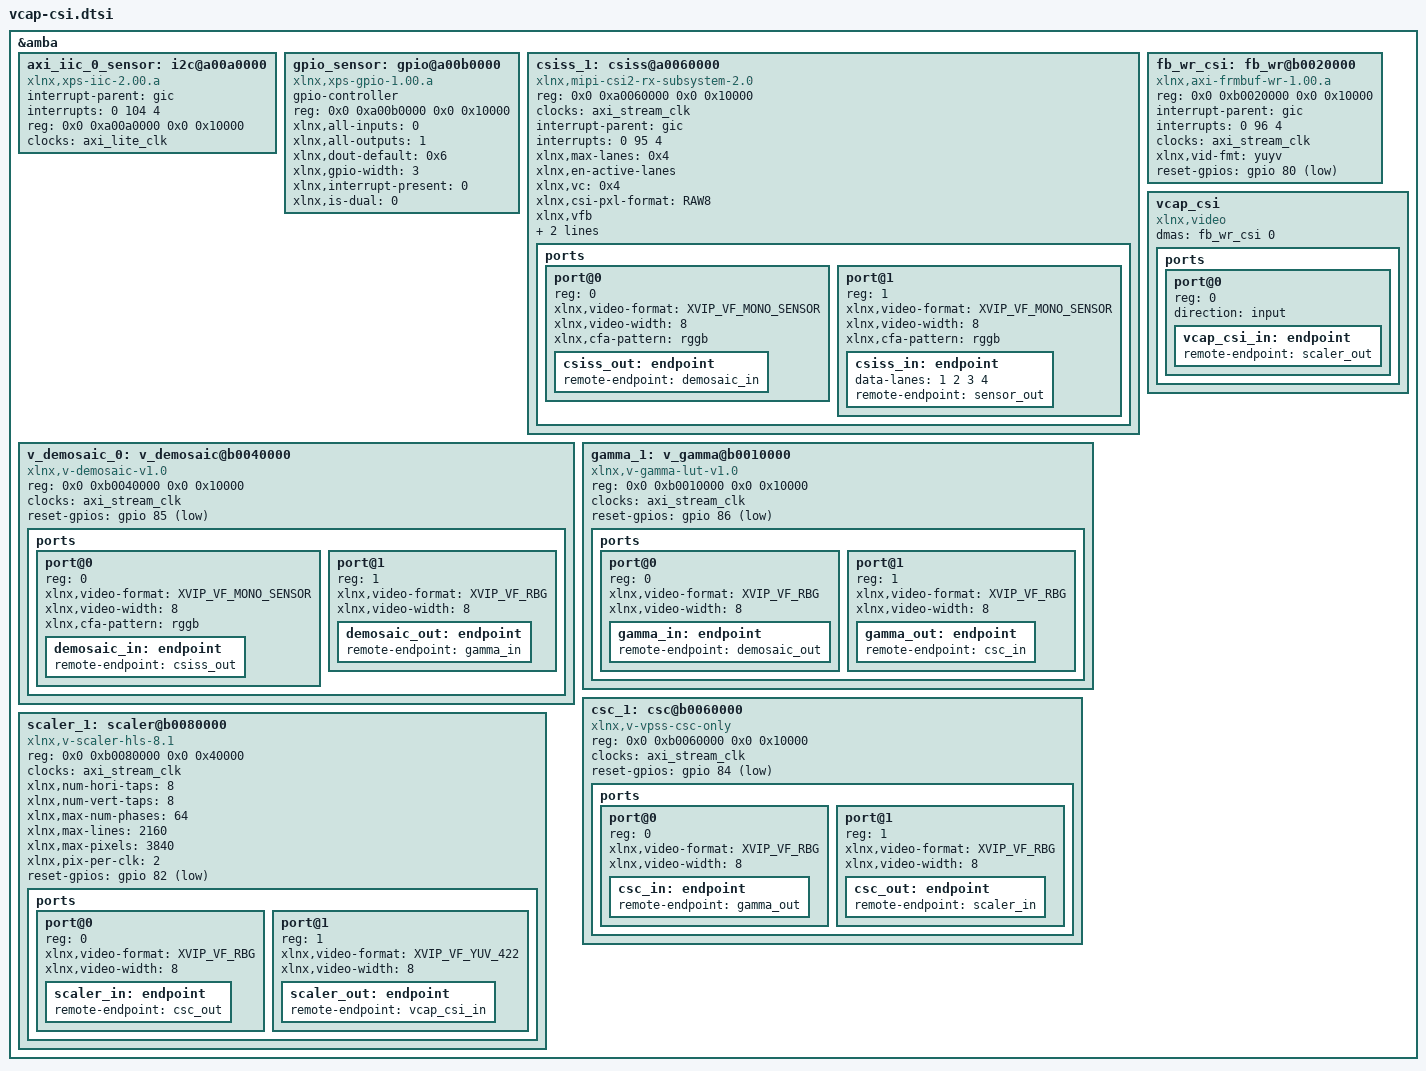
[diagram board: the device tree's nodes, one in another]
#include <dt-bindings/media/xilinx-vip.h>

&amba {
	axi_iic_0_sensor: i2c@a00a0000 {
		#address-cells = <1>;
		#size-cells = <0>;
		compatible = "xlnx,xps-iic-2.00.a";
		interrupt-parent = <&gic>;
		interrupts = <0 104 4>;
		reg = <0x0 0xa00a0000 0x0 0x10000>;
		clocks = <&axi_lite_clk>;
	};

	gpio_sensor: gpio@a00b0000 {
		#gpio-cells = <2>;
		compatible = "xlnx,xps-gpio-1.00.a";
		gpio-controller;
		reg = <0x0 0xa00b0000 0x0 0x10000>;

		xlnx,all-inputs = <0>;
		xlnx,all-outputs = <1>;
		xlnx,dout-default = <0x6>;
		xlnx,gpio-width = <3>;
		xlnx,interrupt-present = <0>;
		xlnx,is-dual = <0>;
	} ;

	csiss_1: csiss@a0060000 {
		compatible = "xlnx,mipi-csi2-rx-subsystem-2.0";
		reg = <0x0 0xa0060000 0x0 0x10000>;
		clocks = <&axi_stream_clk>;
		interrupt-parent = <&gic>;
		interrupts = <0 95 4>;

		xlnx,max-lanes = <0x4>;
		xlnx,en-active-lanes;
		xlnx,vc = <0x4>;
		xlnx,csi-pxl-format = "RAW8";
		xlnx,vfb;
		xlnx,ppc = <0x4>;
		xlnx,axis-tdata-width = <0x20>;

		ports {
			#address-cells = <1>;
			#size-cells = <0>;

			port@0 {
				reg = <0>;

				xlnx,video-format = <XVIP_VF_MONO_SENSOR>;
				xlnx,video-width = <8>;
				xlnx,cfa-pattern = "rggb";

				csiss_out: endpoint {
					remote-endpoint = <&demosaic_in>;
				};
			};
			port@1 {
				reg = <1>;

				xlnx,video-format = <XVIP_VF_MONO_SENSOR>;
				xlnx,video-width = <8>;
				xlnx,cfa-pattern = "rggb";

				csiss_in: endpoint {
					data-lanes = <1 2 3 4>;
					remote-endpoint = <&sensor_out>;
				};
			};
		};
	};

	v_demosaic_0: v_demosaic@b0040000 {
		compatible = "xlnx,v-demosaic-v1.0";
		reg = <0x0 0xb0040000 0x0 0x10000>;
		clocks = <&axi_stream_clk>;

		reset-gpios = <&gpio 85 1>;

		ports {
			#address-cells = <1>;
			#size-cells = <0>;

			port@0 {
				reg = <0>;

				xlnx,video-format = <XVIP_VF_MONO_SENSOR>;
				xlnx,video-width = <8>;
				xlnx,cfa-pattern = "rggb";

				demosaic_in: endpoint {
					remote-endpoint = <&csiss_out>;
				};
			};

			port@1 {
				reg = <1>;

				xlnx,video-format = <XVIP_VF_RBG>;
				xlnx,video-width = <8>;

				demosaic_out: endpoint {
					remote-endpoint = <&gamma_in>;
				};
			};
		};
	};

	gamma_1: v_gamma@b0010000 {
		compatible = "xlnx,v-gamma-lut-v1.0";
		reg = <0x0 0xb0010000 0x0 0x10000>;
		clocks = <&axi_stream_clk>;

		reset-gpios = <&gpio 86 1>;

		ports {
			#address-cells = <1>;
			#size-cells = <0>;

			port@0 {
				reg = <0>;

				xlnx,video-format = <XVIP_VF_RBG>;
				xlnx,video-width = <8>;

				gamma_in: endpoint {
					remote-endpoint = <&demosaic_out>;
				};
			};

			port@1 {
				reg = <1>;

				xlnx,video-format = <XVIP_VF_RBG>;
				xlnx,video-width = <8>;

				gamma_out: endpoint {
					remote-endpoint = <&csc_in>;
				};
			};
		};
	};

	csc_1: csc@b0060000 {
		compatible = "xlnx,v-vpss-csc-only";
		reg = <0x0 0xb0060000 0x0 0x10000>;
		clocks = <&axi_stream_clk>;

		reset-gpios = <&gpio 84 1>;

		ports {
			#address-cells = <1>;
			#size-cells = <0>;

			port@0 {
				reg = <0>;

				xlnx,video-format = <XVIP_VF_RBG>;
				xlnx,video-width = <8>;

				csc_in: endpoint {
					remote-endpoint = <&gamma_out>;
				};
			};
			port@1 {
				reg = <1>;

				xlnx,video-format = <XVIP_VF_RBG>;
				xlnx,video-width = <8>;

				csc_out: endpoint {
					remote-endpoint = <&scaler_in>;
				};
			};
		};
	};

	scaler_1: scaler@b0080000 {
		compatible = "xlnx,v-scaler-hls-8.1";
		reg = <0x0 0xb0080000 0x0 0x40000>;
		clocks = <&axi_stream_clk>;

		xlnx,num-hori-taps = <8>;
		xlnx,num-vert-taps = <8>;
		xlnx,max-num-phases = <64>;
		xlnx,max-lines = <2160>;
		xlnx,max-pixels = <3840>;
		xlnx,pix-per-clk = <2>;

		reset-gpios = <&gpio 82 1>;

		ports {
			#address-cells = <1>;
			#size-cells = <0>;

			port@0 {
				reg = <0>;

				xlnx,video-format = <XVIP_VF_RBG>;
				xlnx,video-width = <8>;

				scaler_in: endpoint {
					remote-endpoint = <&csc_out>;
				};
			};
			port@1 {
				reg = <1>;

				xlnx,video-format = <XVIP_VF_YUV_422>;
				xlnx,video-width = <8>;

				scaler_out: endpoint {
					remote-endpoint = <&vcap_csi_in>;
				};
			};
		};
	};

	fb_wr_csi: fb_wr@b0020000 {
		compatible = "xlnx,axi-frmbuf-wr-1.00.a";
		reg = <0x0 0xb0020000 0x0 0x10000>;
		#dma-cells = <1>;
		interrupt-parent = <&gic>;
		interrupts = <0 96 4>;
		clocks = <&axi_stream_clk>;
		clock-names = "axis";
		xlnx,vid-fmt = "yuyv";
		reset-gpios = <&gpio 80 1>;
	};

	vcap_csi {
		compatible = "xlnx,video";
		dmas = <&fb_wr_csi 0>;
		dma-names = "port0";

		ports {
			#address-cells = <1>;
			#size-cells = <0>;

			port@0 {
				reg = <0>;
				direction = "input";

				vcap_csi_in: endpoint {
					remote-endpoint = <&scaler_out>;
				};
			};
		};
	};
};
